# apollo3p register map
Vendor: Ambiq Micro; Series: Apollo; File version: 1.0
CPU: CM4 r1p0, little endian, MPU, FPU, I-cache, D-cache, VTOR, ITCM, DTCM, 3 interrupt priority bits, 0 interrupts
Registers are 32-bit, read-write, reset 0x0 unless marked. A register's access mark holds for its fields unless they carry their own. Offsets are from the block's base; [hi:lo] are bit positions; {n}, {i} and the like mark numbered series; 'fields as' and 'values as' point back to an identical list.

## CTIMER (part 2 of 3) — Counter/Timer
Base 0x40008000
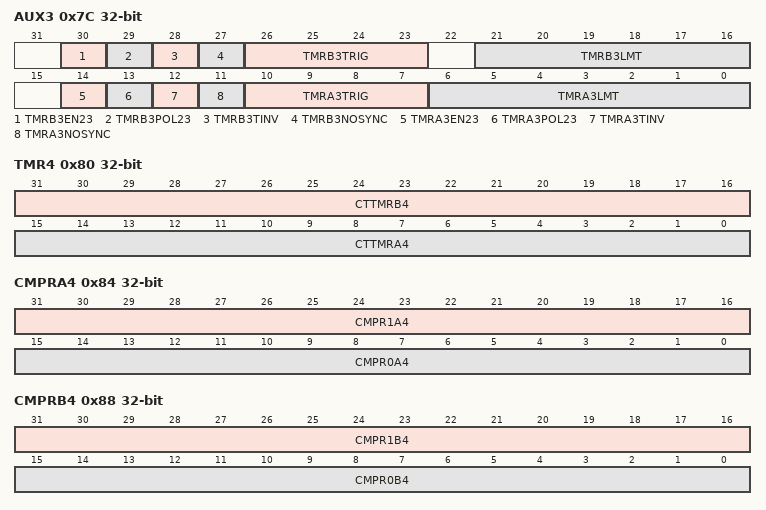
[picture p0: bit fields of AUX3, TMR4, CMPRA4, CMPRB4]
0x7C AUX3 — Control bit fields for both halves of timer 0.
  [30] TMRB3EN23 — Counter/Timer B3 Upper compare enable.
    1=DIS (Disable enhanced functions.); 0=EN (Enable enhanced functions.)
  [29] TMRB3POL23 — Upper output polarity
    0=NORM (Upper output normal polarity); 1=INV (Upper output inverted polarity.)
  [28] TMRB3TINV — Counter/Timer B3 Invert on trigger.
    0=DIS (Disable invert on trigger); 1=EN (Enable invert on trigger)
  [27] TMRB3NOSYNC — Source clock synchronization control.
    0=DIS (Synchronization on source clock); 1=NOSYNC (No synchronization on source clock)
  [26:23] TMRB3TRIG — Counter/Timer B3 Trigger Select.
    0=DIS (Trigger source is disabled.); 1=A3OUT (Trigger source is CTIMERA3 OUT.); 2=B2OUT (Trigger source is CTIMERB2 OUT.); 3=A2OUT (Trigger source is CTIMERA2 OUT.); 4=A4OUT (Trigger source is CTIMERA4 OUT.); 5=B4OUT (Trigger source is CTIMERB4 OUT.); 6=A6OUT (Trigger source is CTIMERA6 OUT.); 7=B6OUT (Trigger source is CTIMERB6 OUT.); 8=B5OUT2 (Trigger source is CTIMERB5 OUT2.); 9=A5OUT2 (Trigger source is CTIMERA5 OUT2.); 10=A1OUT2 (Trigger source is CTIMERA1 OUT2.); 11=B1OUT2 (Trigger source is CTIMERB1 OUT2.); 12=A6OUT2DUAL (Trigger source is CTIMERA6 OUT2, dual edge.); 13=A7OUT2DUAL (Trigger source is CTIMERA7 OUT2, dual edge.); 14=B2OUT2DUAL (Trigger source is CTIMERB2 OUT2, dual edge.); 15=A2OUT2DUAL (Trigger source is CTIMERA2 OUT2, dual edge.)
  [21:16] TMRB3LMT — Counter/Timer B3 Pattern Limit Count.
  [14] TMRA3EN23 — Counter/Timer A3 Upper compare enable.
    values as TMRB3EN23
  [13] TMRA3POL23 — Counter/Timer A3 Upper output polarity
    values as TMRB3POL23
  [12] TMRA3TINV — Counter/Timer A3 Invert on trigger.
    values as TMRB3TINV
  [11] TMRA3NOSYNC — Source clock synchronization control.
    values as TMRB3NOSYNC
  [10:7] TMRA3TRIG — Counter/Timer A3 Trigger Select.
    0=DIS (Trigger source is disabled.); 1=B3OUT (Trigger source is CTIMERB3 OUT.); 2=B2OUT (Trigger source is CTIMERB2 OUT.); 3=A2OUT (Trigger source is CTIMERA2 OUT.); 4=A4OUT (Trigger source is CTIMERA4 OUT.); 5=B4OUT (Trigger source is CTIMERB4 OUT.); 6=A7OUT (Trigger source is CTIMERA7 OUT.); 7=B7OUT (Trigger source is CTIMERB7 OUT.); 8=B5OUT2 (Trigger source is CTIMERB5 OUT2.); 9=A5OUT2 (Trigger source is CTIMERA5 OUT2.); 10=A1OUT2 (Trigger source is CTIMERA1 OUT2.); 11=B1OUT2 (Trigger source is CTIMERB1 OUT2.); 12=A6OUT2DUAL (Trigger source is CTIMERA6 OUT2, dual edge.); 13=A7OUT2DUAL (Trigger source is CTIMERA7 OUT2, dual edge.); 14=B2OUT2DUAL (Trigger source is CTIMERB2 OUT2, dual edge.); 15=A2OUT2DUAL (Trigger source is CTIMERA2 OUT2, dual edge.)
  [6:0] TMRA3LMT — Counter/Timer A3 Pattern Limit Count.
0x80 TMR4 — This register holds the running time or event count, either for each 16 bit half or for the whole 32 bit count when the pair is linked.
  [31:16] CTTMRB4 — Counter/Timer B4.
  [15:0] CTTMRA4 — Counter/Timer A4.
0x84 CMPRA4 — Compare limits for timer half A.
  [31:16] CMPR1A4 — Counter/Timer A4 Compare Register 1. Holds the upper limit for timer half A.
  [15:0] CMPR0A4 — Counter/Timer A4 Compare Register 0. Holds the lower limit for timer half A.
0x88 CMPRB4 — Compare limits for timer half B.
  [31:16] CMPR1B4 — Counter/Timer B4 Compare Register 1. Holds the upper limit for timer half B.
  [15:0] CMPR0B4 — Counter/Timer B4 Compare Register 0. Holds the lower limit for timer half B.
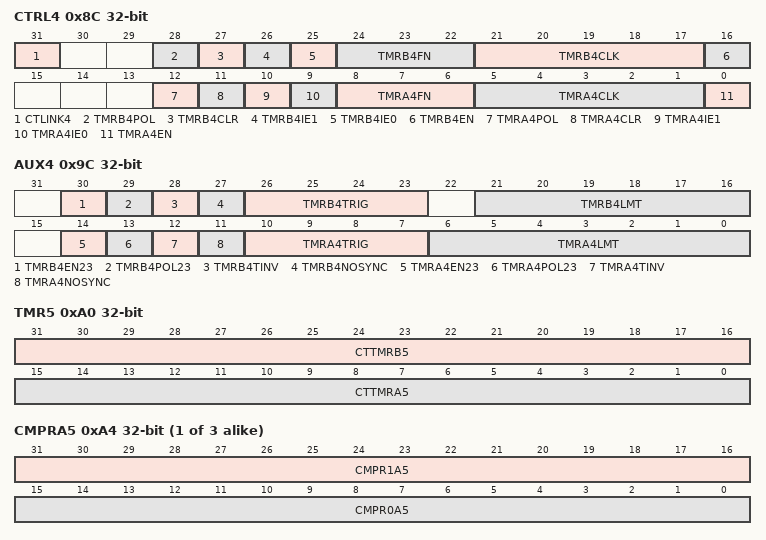
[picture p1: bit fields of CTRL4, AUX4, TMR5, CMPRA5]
0x8C CTRL4 — Control bit fields for both halves of timer 4.
  [31] CTLINK4 — Counter/Timer A4/B4 Link bit.
    0=TWO_16BIT_TIMERS (Use A4/B4 timers as two independent 16-bit timers (default).); 1=32BIT_TIMER (Link A4/B4 timers into a single 32-bit timer.)
  [28] TMRB4POL — Counter/Timer B4 output polarity.
    0=NORMAL (The polarity of the TMRPINB4 pin is the same as the timer output.); 1=INVERTED (The polarity of the TMRPINB4 pin is the inverse of the timer output.)
  [27] TMRB4CLR — Counter/Timer B4 Clear bit.
    0=RUN (Allow counter/timer B4 to run); 1=CLEAR (Holds counter/timer B4 at 0x0000.)
  [26] TMRB4IE1 — Counter/Timer B4 Interrupt Enable bit for COMPR1.
    0=DIS (Disable counter/timer B4 from generating an interrupt based on COMPR1.); 1=EN (Enable counter/timer B4 to generate an interrupt based on COMPR1.)
  [25] TMRB4IE0 — Counter/Timer B4 Interrupt Enable bit for COMPR0.
    0=DIS (Disable counter/timer B4 from generating an interrupt based on COMPR0.); 1=EN (Enable counter/timer B4 to generate an interrupt based on COMPR0)
  [24:22] TMRB4FN — Counter/Timer B4 Function Select.
    0=SINGLECOUNT (Single count (output toggles and sticks). Count to CMPR0B4, stop.); 1=REPEATEDCOUNT (Repeated count (periodic 1-clock-cycle-wide pulses). Count to CMPR0B4, restart.); 2=PULSE_ONCE (Pulse once (aka one-shot). Count to CMPR0B4, assert, count to CMPR1B4, deassert, stop.); 3=PULSE_CONT (Pulse continuously. Count to CMPR0B4, assert, count to CMPR1B4, deassert, restart.); 4=SINGLEPATTERN; 5=REPEATPATTERN (Repeated pattern.); 6=CONTINUOUS (Continuous run (aka Free Run). Count continuously.); 7=ALTPWN (Alternate PWM)
  [21:17] TMRB4CLK — Counter/Timer B4 Clock Select.
    0=TMRPIN (Clock source is TMRPINB.); 1=HFRC_DIV4 (Clock source is the HFRC / 4); 2=HFRC_DIV16 (Clock source is HFRC / 16); 3=HFRC_DIV256 (Clock source is HFRC / 256); 4=HFRC_DIV1024 (Clock source is HFRC / 1024); 5=HFRC_DIV4K (Clock source is HFRC / 4096); 6=XT (Clock source is the XT (uncalibrated).); 7=XT_DIV2 (Clock source is XT / 2); 8=XT_DIV16 (Clock source is XT / 16); 9=XT_DIV128 (Clock source is XT / 128); 10=LFRC_DIV2 (Clock source is LFRC / 2); 11=LFRC_DIV32 (Clock source is LFRC / 32); 12=LFRC_DIV1K (Clock source is LFRC / 1024); 13=LFRC (Clock source is LFRC); 14=RTC_100HZ (Clock source is 100 Hz from the current RTC oscillator.); 15=HCLK_DIV4 (Clock source is HCLK / 4 (note: this clock is only available when MCU is in active mode)); 16=XT_DIV4 (Clock source is XT / 4); 17=XT_DIV8 (Clock source is XT / 8); 18=XT_DIV32 (Clock source is XT / 32); 20=CTMRA4 (Clock source is CTIMERA4 OUT.); 21=CTMRA1 (Clock source is CTIMERA1 OUT.); 22=CTMRB1 (Clock source is CTIMERB1 OUT.); 23=CTMRA5 (Clock source is CTIMERA5 OUT.); 24=CTMRB5 (Clock source is CTIMERB5 OUT.); 25=CTMRB0 (Clock source is CTIMERB0 OUT.); 26=CTMRB2 (Clock source is CTIMERB2 OUT.); 27=CTMRB3 (Clock source is CTIMERB3 OUT.); 28=CTMRB6 (Clock source is CTIMERB6 OUT.); 29=BUCKBLE (Clock source is BLE buck converter TON pulses.); 30=BUCKB (Clock source is Memory buck converter TON pulses.); 31=BUCKA (Clock source is CPU buck converter TON pulses.)
  [16] TMRB4EN — Counter/Timer B4 Enable bit.
    0=DIS (Counter/Timer B4 Disable.); 1=EN (Counter/Timer B4 Enable.)
  [12] TMRA4POL — Counter/Timer A4 output polarity.
    0=NORMAL (The polarity of the TMRPINA4 pin is the same as the timer output.); 1=INVERTED (The polarity of the TMRPINA4 pin is the inverse of the timer output.)
  [11] TMRA4CLR — Counter/Timer A4 Clear bit.
    0=RUN (Allow counter/timer A4 to run); 1=CLEAR (Holds counter/timer A4 at 0x0000.)
  [10] TMRA4IE1 — Counter/Timer A4 Interrupt Enable bit based on COMPR1.
    0=DIS (Disable counter/timer A4 from generating an interrupt based on COMPR1.); 1=EN (Enable counter/timer A4 to generate an interrupt based on COMPR1.)
  [9] TMRA4IE0 — Counter/Timer A4 Interrupt Enable bit based on COMPR0.
    0=DIS (Disable counter/timer A4 from generating an interrupt based on COMPR0.); 1=EN (Enable counter/timer A4 to generate an interrupt based on COMPR0.)
  [8:6] TMRA4FN — Counter/Timer A4 Function Select.
    0=SINGLECOUNT (Single count (output toggles and sticks). Count to CMPR0A4, stop.); 1=REPEATEDCOUNT (Repeated count (periodic 1-clock-cycle-wide pulses). Count to CMPR0A4, restart.); 2=PULSE_ONCE (Pulse once (aka one-shot). Count to CMPR0A4, assert, count to CMPR1A4, deassert, stop.); 3=PULSE_CONT (Pulse continuously. Count to CMPR0A4, assert, count to CMPR1A4, deassert, restart.); 4=SINGLEPATTERN; 5=REPEATPATTERN (Repeated pattern.); 6=CONTINUOUS (Continuous run (aka Free Run). Count continuously.); 7=ALTPWN (Alternate PWM)
  [5:1] TMRA4CLK — Counter/Timer A4 Clock Select.
    0=TMRPIN (Clock source is TMRPINA.); 1=HFRC_DIV4 (Clock source is the HFRC / 4); 2=HFRC_DIV16 (Clock source is HFRC / 16); 3=HFRC_DIV256 (Clock source is HFRC / 256); 4=HFRC_DIV1024 (Clock source is HFRC / 1024); 5=HFRC_DIV4K (Clock source is HFRC / 4096); 6=XT (Clock source is the XT (uncalibrated).); 7=XT_DIV2 (Clock source is XT / 2); 8=XT_DIV16 (Clock source is XT / 16); 9=XT_DIV128 (Clock source is XT / 128); 10=LFRC_DIV2 (Clock source is LFRC / 2); 11=LFRC_DIV32 (Clock source is LFRC / 32); 12=LFRC_DIV1K (Clock source is LFRC / 1024); 13=LFRC (Clock source is LFRC); 14=RTC_100HZ (Clock source is 100 Hz from the current RTC oscillator.); 15=HCLK_DIV4 (Clock source is HCLK / 4. (note: this clock is only available when MCU is in active mode)); 16=XT_DIV4 (Clock source is XT / 4); 17=XT_DIV8 (Clock source is XT / 8); 18=XT_DIV32 (Clock source is XT / 32); 20=CTMRB4 (Clock source is CTIMERB4 OUT.); 21=CTMRA1 (Clock source is CTIMERA1 OUT.); 22=CTMRB1 (Clock source is CTIMERB1 OUT.); 23=CTMRA5 (Clock source is CTIMERA5 OUT.); 24=CTMRB5 (Clock source is CTIMERB5 OUT.); 25=CTMRB0 (Clock source is CTIMERB0 OUT.); 26=CTMRB2 (Clock source is CTIMERB2 OUT.); 27=CTMRB3 (Clock source is CTIMERB3 OUT.); 28=CTMRB6 (Clock source is CTIMERB6 OUT.); 29=BUCKBLE (Clock source is BLE buck converter TON pulses.); 30=BUCKB (Clock source is Memory buck converter TON pulses.); 31=BUCKA (Clock source is CPU buck converter TON pulses.)
  [0] TMRA4EN — Counter/Timer A4 Enable bit.
    0=DIS (Counter/Timer A4 Disable.); 1=EN (Counter/Timer A4 Enable.)
0x9C AUX4 — Control bit fields for both halves of timer 4.
  [30] TMRB4EN23 — Counter/Timer B4 Upper compare enable.
    values as AUX3.TMRB3EN23
  [29] TMRB4POL23 — Upper output polarity
    values as AUX3.TMRB3POL23
  [28] TMRB4TINV — Counter/Timer B4 Invert on trigger.
    values as AUX3.TMRB3TINV
  [27] TMRB4NOSYNC — Source clock synchronization control.
    values as AUX3.TMRB3NOSYNC
  [26:23] TMRB4TRIG — Counter/Timer B4 Trigger Select.
    0=DIS (Trigger source is disabled.); 1=A4OUT (Trigger source is CTIMERA4 OUT.); 2=B3OUT (Trigger source is CTIMERB3 OUT.); 3=A3OUT (Trigger source is CTIMERA3 OUT.); 4=A7OUT (Trigger source is CTIMERA7 OUT.); 5=B7OUT (Trigger source is CTIMERB7 OUT.); 6=A1OUT (Trigger source is CTIMERA1 OUT.); 7=B1OUT (Trigger source is CTIMERB1 OUT.); 8=B3OUT2 (Trigger source is CTIMERB3 OUT2.); 9=A3OUT2 (Trigger source is CTIMERA3 OUT2.); 10=A1OUT2 (Trigger source is CTIMERA1 OUT2.); 11=B1OUT2 (Trigger source is CTIMERB1 OUT2.); 12=A6OUT2DUAL (Trigger source is CTIMERA6 OUT2, dual edge.); 13=A7OUT2DUAL (Trigger source is CTIMERA7 OUT2, dual edge.); 14=B5OUT2DUAL (Trigger source is CTIMERB5 OUT2, dual edge.); 15=A5OUT2DUAL (Trigger source is CTIMERA5 OUT2, dual edge.)
  [21:16] TMRB4LMT — Counter/Timer B4 Pattern Limit Count.
  [14] TMRA4EN23 — Counter/Timer A4 Upper compare enable.
    values as AUX3.TMRB3EN23
  [13] TMRA4POL23 — Counter/Timer A4 Upper output polarity
    values as AUX3.TMRB3POL23
  [12] TMRA4TINV — Counter/Timer A4 Invert on trigger.
    values as AUX3.TMRB3TINV
  [11] TMRA4NOSYNC — Source clock synchronization control.
    values as AUX3.TMRB3NOSYNC
  [10:7] TMRA4TRIG — Counter/Timer A4 Trigger Select.
    0=DIS (Trigger source is disabled.); 1=STIMER (Trigger source is STimer Interrupt. Only Active When CTLINK==1 and TMRB4TRIG!=0. TMRB4TRIG selects an STIMER interrupt); 2=B3OUT (Trigger source is CTIMERB3 OUT.); 3=A3OUT (Trigger source is CTIMERA3 OUT.); 4=A6OUT (Trigger source is CTIMERA6 OUT.); 5=B6OUT (Trigger source is CTIMERB6 OUT.); 6=A2OUT (Trigger source is CTIMERA2 OUT.); 7=B2OUT (Trigger source is CTIMERB2 OUT.); 8=B3OUT2 (Trigger source is CTIMERB3 OUT2.); 9=A3OUT2 (Trigger source is CTIMERA3 OUT2.); 10=A1OUT2 (Trigger source is CTIMERA1 OUT2.); 11=B1OUT2 (Trigger source is CTIMERB1 OUT2.); 12=A6OUT2DUAL (Trigger source is CTIMERA6 OUT2, dual edge.); 13=A7OUT2DUAL (Trigger source is CTIMERA7 OUT2, dual edge.); 14=B5OUT2DUAL (Trigger source is CTIMERB5 OUT2, dual edge.); 15=A5OUT2DUAL (Trigger source is CTIMERA5 OUT2, dual edge.)
  [6:0] TMRA4LMT — Counter/Timer A4 Pattern Limit Count.
0xA0 TMR5 — This register holds the running time or event count, either for each 16 bit half or for the whole 32 bit count when the pair is linked.
  [31:16] CTTMRB5 — Counter/Timer B5.
  [15:0] CTTMRA5 — Counter/Timer A5.
{0x4+0x20*i} CMPRA{i} (i=5..7) — This register holds the compare limits for timer half A.
  [31:16] CMPR1A{i} — Counter/Timer A{i} Compare Register 1.
  [15:0] CMPR0A{i} — Counter/Timer A{i} Compare Register 0.
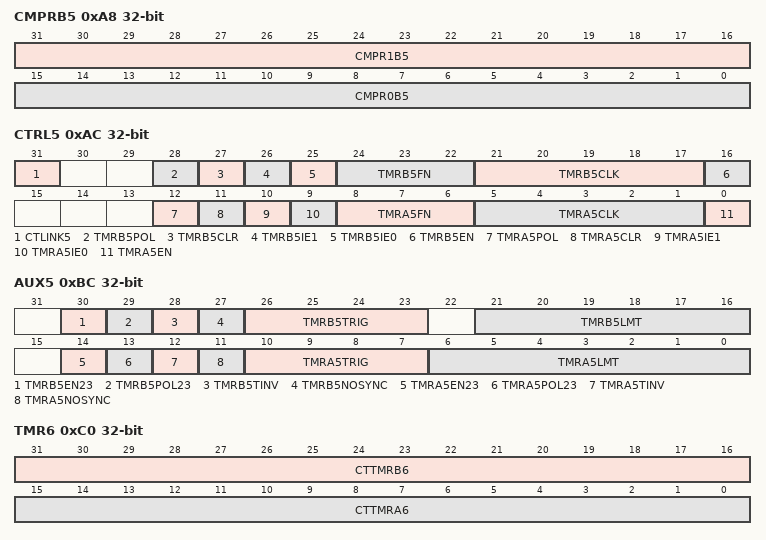
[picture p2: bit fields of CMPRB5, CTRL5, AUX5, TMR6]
0xA8 CMPRB5 — This register holds the compare limits for timer half B.
  [31:16] CMPR1B5 — Counter/Timer B5 Compare Register 1.
  [15:0] CMPR0B5 — Counter/Timer B5 Compare Register 0.
0xAC CTRL5 — Control bit fields for both halves of timer 0.
  [31] CTLINK5 — Counter/Timer A5/B5 Link bit.
    0=TWO_16BIT_TIMERS (Use A5/B5 timers as two independent 16-bit timers (default).); 1=32BIT_TIMER (Link A5/B5 timers into a single 32-bit timer.)
  [28] TMRB5POL — Counter/Timer B5 output polarity.
    0=NORMAL (The polarity of the TMRPINB5 pin is the same as the timer output.); 1=INVERTED (The polarity of the TMRPINB5 pin is the inverse of the timer output.)
  [27] TMRB5CLR — Counter/Timer B5 Clear bit.
    0=RUN (Allow counter/timer B5 to run); 1=CLEAR (Holds counter/timer B5 at 0x0000.)
  [26] TMRB5IE1 — Counter/Timer B5 Interrupt Enable bit for COMPR1.
    0=DIS (Disable counter/timer B5 from generating an interrupt based on COMPR1.); 1=EN (Enable counter/timer B5 to generate an interrupt based on COMPR1.)
  [25] TMRB5IE0 — Counter/Timer B5 Interrupt Enable bit for COMPR0.
    0=DIS (Disable counter/timer B5 from generating an interrupt based on COMPR0.); 1=EN (Enable counter/timer B5 to generate an interrupt based on COMPR0)
  [24:22] TMRB5FN — Counter/Timer B5 Function Select.
    0=SINGLECOUNT (Single count (output toggles and sticks). Count to CMPR0B5, stop.); 1=REPEATEDCOUNT (Repeated count (periodic 1-clock-cycle-wide pulses). Count to CMPR0B5, restart.); 2=PULSE_ONCE (Pulse once (aka one-shot). Count to CMPR0B5, assert, count to CMPR1B5, deassert, stop.); 3=PULSE_CONT (Pulse continuously. Count to CMPR0B5, assert, count to CMPR1B5, deassert, restart.); 4=SINGLEPATTERN; 5=REPEATPATTERN (Repeated pattern.); 6=CONTINUOUS (Continuous run (aka Free Run). Count continuously.); 7=ALTPWN (Alternate PWM)
  [21:17] TMRB5CLK — Counter/Timer B5 Clock Select.
    0=TMRPIN (Clock source is TMRPINB.); 1=HFRC_DIV4 (Clock source is the HFRC / 4); 2=HFRC_DIV16 (Clock source is HFRC / 16); 3=HFRC_DIV256 (Clock source is HFRC / 256); 4=HFRC_DIV1024 (Clock source is HFRC / 1024); 5=HFRC_DIV4K (Clock source is HFRC / 4096); 6=XT (Clock source is the XT (uncalibrated).); 7=XT_DIV2 (Clock source is XT / 2); 8=XT_DIV16 (Clock source is XT / 16); 9=XT_DIV128 (Clock source is XT / 128); 10=LFRC_DIV2 (Clock source is LFRC / 2); 11=LFRC_DIV32 (Clock source is LFRC / 32); 12=LFRC_DIV1K (Clock source is LFRC / 1024); 13=LFRC (Clock source is LFRC); 14=RTC_100HZ (Clock source is 100 Hz from the current RTC oscillator.); 15=HCLK_DIV4 (Clock source is HCLK / 4 (note: this clock is only available when MCU is in active mode)); 16=XT_DIV4 (Clock source is XT / 4); 17=XT_DIV8 (Clock source is XT / 8); 18=XT_DIV32 (Clock source is XT / 32); 20=CTMRA5 (Clock source is CTIMERA5 OUT.); 21=CTMRA0 (Clock source is CTIMERA0 OUT.); 22=CTMRB0 (Clock source is CTIMERB0 OUT.); 23=CTMRA6 (Clock source is CTIMERA6 OUT.); 24=CTMRB6 (Clock source is CTIMERB6 OUT.); {v}=CTMRB{v-24} (Clock source is CTIMERB{v-24} OUT.) (v=25..28); 29=BUCKBLE (Clock source is BLE buck converter TON pulses.); 30=BUCKB (Clock source is Memory buck converter TON pulses.); 31=BUCKA (Clock source is CPU buck converter TON pulses.)
  [16] TMRB5EN — Counter/Timer B5 Enable bit.
    0=DIS (Counter/Timer B5 Disable.); 1=EN (Counter/Timer B5 Enable.)
  [12] TMRA5POL — Counter/Timer A5 output polarity.
    0=NORMAL (The polarity of the TMRPINA5 pin is the same as the timer output.); 1=INVERTED (The polarity of the TMRPINA5 pin is the inverse of the timer output.)
  [11] TMRA5CLR — Counter/Timer A5 Clear bit.
    0=RUN (Allow counter/timer A5 to run); 1=CLEAR (Holds counter/timer A5 at 0x0000.)
  [10] TMRA5IE1 — Counter/Timer A5 Interrupt Enable bit based on COMPR1.
    0=DIS (Disable counter/timer A5 from generating an interrupt based on COMPR1.); 1=EN (Enable counter/timer A5 to generate an interrupt based on COMPR1.)
  [9] TMRA5IE0 — Counter/Timer A5 Interrupt Enable bit based on COMPR0.
    0=DIS (Disable counter/timer A5 from generating an interrupt based on COMPR0.); 1=EN (Enable counter/timer A5 to generate an interrupt based on COMPR0.)
  [8:6] TMRA5FN — Counter/Timer A5 Function Select.
    0=SINGLECOUNT (Single count (output toggles and sticks). Count to CMPR0A5, stop.); 1=REPEATEDCOUNT (Repeated count (periodic 1-clock-cycle-wide pulses). Count to CMPR0A5, restart.); 2=PULSE_ONCE (Pulse once (aka one-shot). Count to CMPR0A5, assert, count to CMPR1A5, deassert, stop.); 3=PULSE_CONT (Pulse continuously. Count to CMPR0A5, assert, count to CMPR1A5, deassert, restart.); 4=SINGLEPATTERN; 5=REPEATPATTERN (Repeated pattern.); 6=CONTINUOUS (Continuous run (aka Free Run). Count continuously.); 7=ALTPWN (Alternate PWM)
  [5:1] TMRA5CLK — Counter/Timer A5 Clock Select.
    0=TMRPIN (Clock source is TMRPINA.); 1=HFRC_DIV4 (Clock source is the HFRC / 4); 2=HFRC_DIV16 (Clock source is HFRC / 16); 3=HFRC_DIV256 (Clock source is HFRC / 256); 4=HFRC_DIV1024 (Clock source is HFRC / 1024); 5=HFRC_DIV4K (Clock source is HFRC / 4096); 6=XT (Clock source is the XT (uncalibrated).); 7=XT_DIV2 (Clock source is XT / 2); 8=XT_DIV16 (Clock source is XT / 16); 9=XT_DIV128 (Clock source is XT / 128); 10=LFRC_DIV2 (Clock source is LFRC / 2); 11=LFRC_DIV32 (Clock source is LFRC / 32); 12=LFRC_DIV1K (Clock source is LFRC / 1024); 13=LFRC (Clock source is LFRC); 14=RTC_100HZ (Clock source is 100 Hz from the current RTC oscillator.); 15=HCLK_DIV4 (Clock source is HCLK / 4 (note: this clock is only available when MCU is in active mode)); 16=XT_DIV4 (Clock source is XT / 4); 17=XT_DIV8 (Clock source is XT / 8); 18=XT_DIV32 (Clock source is XT / 32); 20=CTMRB5 (Clock source is CTIMERB5 OUT.); 21=CTMRA0 (Clock source is CTIMERA0 OUT.); 22=CTMRB0 (Clock source is CTIMERB0 OUT.); 23=CTMRA6 (Clock source is CTIMERA6 OUT.); 24=CTMRB6 (Clock source is CTIMERB6 OUT.); {v}=CTMRB{v-24} (Clock source is CTIMERB{v-24} OUT.) (v=25..28); 29=BUCKBLE (Clock source is BLE buck converter TON pulses.); 30=BUCKB (Clock source is Memory buck converter TON pulses.); 31=BUCKA (Clock source is CPU buck converter TON pulses.)
  [0] TMRA5EN — Counter/Timer A5 Enable bit.
    0=DIS (Counter/Timer A5 Disable.); 1=EN (Counter/Timer A5 Enable.)
0xBC AUX5 — Control bit fields for both halves of timer 0.
  [30] TMRB5EN23 — Counter/Timer B5 Upper compare enable.
    values as AUX3.TMRB3EN23
  [29] TMRB5POL23 — Upper output polarity
    values as AUX3.TMRB3POL23
  [28] TMRB5TINV — Counter/Timer B5 Invert on trigger.
    values as AUX3.TMRB3TINV
  [27] TMRB5NOSYNC — Source clock synchronization control.
    values as AUX3.TMRB3NOSYNC
  [26:23] TMRB5TRIG — Counter/Timer B5 Trigger Select.
    0=DIS (Trigger source is disabled.); 1=A5OUT (Trigger source is CTIMERA5 OUT.); 2=B3OUT (Trigger source is CTIMERB3 OUT.); 3=A3OUT (Trigger source is CTIMERA3 OUT.); 4=A6OUT (Trigger source is CTIMERA6 OUT.); 5=B6OUT (Trigger source is CTIMERB6 OUT.); 6=A1OUT (Trigger source is CTIMERA1 OUT.); 7=B1OUT (Trigger source is CTIMERB1 OUT.); 8=B3OUT2 (Trigger source is CTIMERB3 OUT2.); 9=A3OUT2 (Trigger source is CTIMERA3 OUT2.); 10=A0OUT2 (Trigger source is CTIMERA0 OUT2.); 11=B0OUT2 (Trigger source is CTIMERB0 OUT2.); 12=A6OUT2DUAL (Trigger source is CTIMERA6 OUT2, dual edge.); 13=A7OUT2DUAL (Trigger source is CTIMERA7 OUT2, dual edge.); 14=B4OUT2DUAL (Trigger source is CTIMERB4 OUT2, dual edge.); 15=A4OUT2DUAL (Trigger source is CTIMERA4 OUT2, dual edge.)
  [21:16] TMRB5LMT — Counter/Timer B5 Pattern Limit Count.
  [14] TMRA5EN23 — Counter/Timer A5 Upper compare enable.
    values as AUX3.TMRB3EN23
  [13] TMRA5POL23 — Counter/Timer A5 Upper output polarity
    0=NORMAL (Upper output normal polarity); 1=INV (Upper output inverted polarity.)
  [12] TMRA5TINV — Counter/Timer A5 Invert on trigger.
    values as AUX3.TMRB3TINV
  [11] TMRA5NOSYNC — Source clock synchronization control.
    values as AUX3.TMRB3NOSYNC
  [10:7] TMRA5TRIG — Counter/Timer A5 Trigger Select.
    0=DIS (Trigger source is disabled.); 1=STIMER (Trigger source is STimer Interrupt. Only Active When CTLINK==1 and TMRB5TRIG!=0. TMRB5TRIG selects an STIMER interrupt); 2=B3OUT (Trigger source is CTIMERB3 OUT.); 3=A3OUT (Trigger source is CTIMERA3 OUT.); 4=A4OUT (Trigger source is CTIMERA4 OUT.); 5=B4OUT (Trigger source is CTIMERB4 OUT.); 6=A2OUT (Trigger source is CTIMERA2 OUT.); 7=B2OUT (Trigger source is CTIMERB2 OUT.); 8=B3OUT2 (Trigger source is CTIMERB3 OUT2.); 9=A3OUT2 (Trigger source is CTIMERA3 OUT2.); 10=A0OUT2 (Trigger source is CTIMERA0 OUT2.); 11=B0OUT2 (Trigger source is CTIMERB0 OUT2.); 12=A6OUT2DUAL (Trigger source is CTIMERA6 OUT2, dual edge.); 13=A7OUT2DUAL (Trigger source is CTIMERA7 OUT2, dual edge.); 14=B4OUT2DUAL (Trigger source is CTIMERB4 OUT2, dual edge.); 15=A4OUT2DUAL (Trigger source is CTIMERA4 OUT2, dual edge.)
  [6:0] TMRA5LMT — Counter/Timer A5 Pattern Limit Count.
0xC0 TMR6 — Counter/Timer 6
  [31:16] CTTMRB6 — Counter/Timer B6.
  [15:0] CTTMRA6 — Counter/Timer A6.
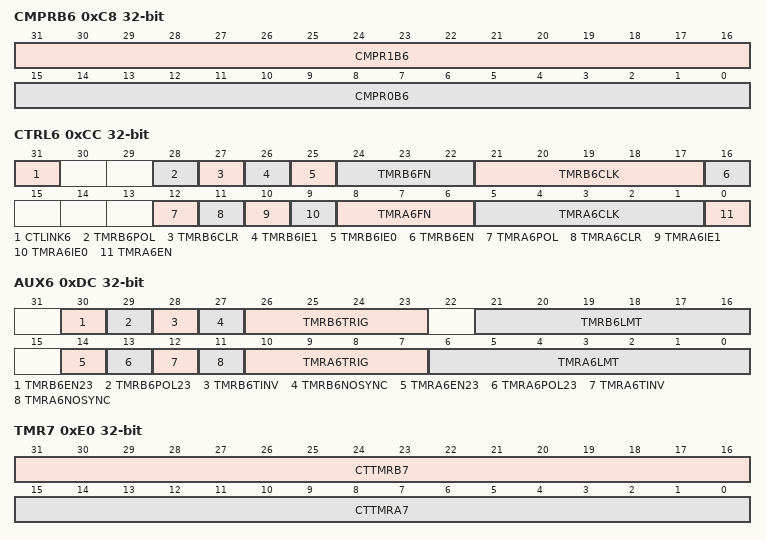
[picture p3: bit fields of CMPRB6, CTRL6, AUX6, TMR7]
0xC8 CMPRB6 — This register holds the compare limits for timer half B.
  [31:16] CMPR1B6 — Counter/Timer B6 Compare Register 1.
  [15:0] CMPR0B6 — Counter/Timer B6 Compare Register 0.
0xCC CTRL6 — This register holds the control bit fields for both halves of timer 6.
  [31] CTLINK6 — Counter/Timer A6/B6 Link bit.
    0=TWO_16BIT_TIMERS (Use A6/B6 timers as two independent 16-bit timers (default).); 1=32BIT_TIMER (Link A6/B6 timers into a single 32-bit timer.)
  [28] TMRB6POL — Counter/Timer B6 output polarity.
    0=NORMAL (The polarity of the TMRPINB6 pin is the same as the timer output.); 1=INVERTED (The polarity of the TMRPINB6 pin is the inverse of the timer output.)
  [27] TMRB6CLR — Counter/Timer B6 Clear bit.
    0=RUN (Allow counter/timer B6 to run); 1=CLEAR (Holds counter/timer B6 at 0x0000.)
  [26] TMRB6IE1 — Counter/Timer B6 Interrupt Enable bit for COMPR1.
    0=DIS (Disable counter/timer B6 from generating an interrupt based on COMPR1.); 1=EN (Enable counter/timer B6 to generate an interrupt based on COMPR1.)
  [25] TMRB6IE0 — Counter/Timer B6 Interrupt Enable bit for COMPR0.
    0=DIS (Disable counter/timer B6 from generating an interrupt based on COMPR0.); 1=EN (Enable counter/timer B6 to generate an interrupt based on COMPR0)
  [24:22] TMRB6FN — Counter/Timer B6 Function Select.
    0=SINGLECOUNT (Single count (output toggles and sticks). Count to CMPR0B6, stop.); 1=REPEATEDCOUNT (Repeated count (periodic 1-clock-cycle-wide pulses). Count to CMPR0B6, restart.); 2=PULSE_ONCE (Pulse once (aka one-shot). Count to CMPR0B6, assert, count to CMPR1B6, deassert, stop.); 3=PULSE_CONT (Pulse continuously. Count to CMPR0B6, assert, count to CMPR1B6, deassert, restart.); 4=SINGLEPATTERN; 5=REPEATPATTERN (Repeated pattern.); 6=CONTINUOUS (Continuous run (aka Free Run). Count continuously.); 7=ALTPWN (Alternate PWM)
  [21:17] TMRB6CLK — Counter/Timer B6 Clock Select.
    0=TMRPIN (Clock source is TMRPINB.); 1=HFRC_DIV4 (Clock source is the HFRC / 4); 2=HFRC_DIV16 (Clock source is HFRC / 16); 3=HFRC_DIV256 (Clock source is HFRC / 256); 4=HFRC_DIV1024 (Clock source is HFRC / 1024); 5=HFRC_DIV4K (Clock source is HFRC / 4096); 6=XT (Clock source is the XT (uncalibrated).); 7=XT_DIV2 (Clock source is XT / 2); 8=XT_DIV16 (Clock source is XT / 16); 9=XT_DIV128 (Clock source is XT / 128); 10=LFRC_DIV2 (Clock source is LFRC / 2); 11=LFRC_DIV32 (Clock source is LFRC / 32); 12=LFRC_DIV1K (Clock source is LFRC / 1024); 13=LFRC (Clock source is LFRC); 14=RTC_100HZ (Clock source is 100 Hz from the current RTC oscillator.); 15=HCLK_DIV4 (Clock source is HCLK / 4 (note: this clock is only available when MCU is in active mode)); 16=XT_DIV4 (Clock source is XT / 4); 17=XT_DIV8 (Clock source is XT / 8); 18=XT_DIV32 (Clock source is XT / 32); 20=CTMRA6 (Clock source is CTIMERA6 OUT.); 21=CTMRA3 (Clock source is CTIMERA3 OUT.); 22=CTMRB3 (Clock source is CTIMERB3 OUT.); 23=CTMRA7 (Clock source is CTIMERA7 OUT.); 24=CTMRB7 (Clock source is CTIMERB7 OUT.); 25=CTMRB0 (Clock source is CTIMERB0 OUT.); 26=CTMRB1 (Clock source is CTIMERB1 OUT.); 27=CTMRB2 (Clock source is CTIMERB2 OUT.); 28=CTMRB4 (Clock source is CTIMERB4 OUT.); 29=BUCKBLE (Clock source is BLE buck converter TON pulses.); 30=BUCKB (Clock source is Memory buck converter TON pulses.); 31=BUCKA (Clock source is CPU buck converter TON pulses.)
  [16] TMRB6EN — Counter/Timer B6 Enable bit.
    0=DIS (Counter/Timer B6 Disable.); 1=EN (Counter/Timer B6 Enable.)
  [12] TMRA6POL — Counter/Timer A6 output polarity.
    0=NORMAL (The polarity of the TMRPINA6 pin is the same as the timer output.); 1=INVERTED (The polarity of the TMRPINA6 pin is the inverse of the timer output.)
  [11] TMRA6CLR — Counter/Timer A6 Clear bit.
    0=RUN (Allow counter/timer A6 to run); 1=CLEAR (Holds counter/timer A6 at 0x0000.)
  [10] TMRA6IE1 — Counter/Timer A6 Interrupt Enable bit based on COMPR1.
    0=DIS (Disable counter/timer A6 from generating an interrupt based on COMPR1.); 1=EN (Enable counter/timer A6 to generate an interrupt based on COMPR1.)
  [9] TMRA6IE0 — Counter/Timer A6 Interrupt Enable bit based on COMPR0.
    0=DIS (Disable counter/timer A6 from generating an interrupt based on COMPR0.); 1=EN (Enable counter/timer A6 to generate an interrupt based on COMPR0.)
  [8:6] TMRA6FN — Counter/Timer A6 Function Select.
    0=SINGLECOUNT (Single count (output toggles and sticks). Count to CMPR0A6, stop.); 1=REPEATEDCOUNT (Repeated count (periodic 1-clock-cycle-wide pulses). Count to CMPR0A6, restart.); 2=PULSE_ONCE (Pulse once (aka one-shot). Count to CMPR0A6, assert, count to CMPR1A6, deassert, stop.); 3=PULSE_CONT (Pulse continuously. Count to CMPR0A6, assert, count to CMPR1A6, deassert, restart.); 4=SINGLEPATTERN; 5=REPEATPATTERN (Repeated pattern.); 6=CONTINUOUS (Continuous run (aka Free Run). Count continuously.); 7=ALTPWN (Alternate PWM)
  [5:1] TMRA6CLK — Counter/Timer A6 Clock Select.
    0=TMRPIN (Clock source is TMRPINA.); 1=HFRC_DIV4 (Clock source is the HFRC / 4); 2=HFRC_DIV16 (Clock source is HFRC / 16); 3=HFRC_DIV256 (Clock source is HFRC / 256); 4=HFRC_DIV1024 (Clock source is HFRC / 1024); 5=HFRC_DIV4K (Clock source is HFRC / 4096); 6=XT (Clock source is the XT (uncalibrated).); 7=XT_DIV2 (Clock source is XT / 2); 8=XT_DIV16 (Clock source is XT / 16); 9=XT_DIV128 (Clock source is XT / 128); 10=LFRC_DIV2 (Clock source is LFRC / 2); 11=LFRC_DIV32 (Clock source is LFRC / 32); 12=LFRC_DIV1K (Clock source is LFRC / 1024); 13=LFRC (Clock source is LFRC); 14=RTC_100HZ (Clock source is 100 Hz from the current RTC oscillator.); 15=HCLK_DIV4 (Clock source is HCLK / 4 (note: this clock is only available when MCU is in active mode)); 16=XT_DIV4 (Clock source is XT / 4); 17=XT_DIV8 (Clock source is XT / 8); 18=XT_DIV32 (Clock source is XT / 32); 20=CTMRB6 (Clock source is CTIMERB6 OUT.); 21=CTMRA3 (Clock source is CTIMERA3 OUT.); 22=CTMRB3 (Clock source is CTIMERB3 OUT.); 23=CTMRA7 (Clock source is CTIMERA7 OUT.); 24=CTMRB7 (Clock source is CTIMERB7 OUT.); 25=CTMRB0 (Clock source is CTIMERB0 OUT.); 26=CTMRB1 (Clock source is CTIMERB1 OUT.); 27=CTMRB2 (Clock source is CTIMERB2 OUT.); 28=CTMRB4 (Clock source is CTIMERB4 OUT.); 29=BUCKBLE (Clock source is BLE buck converter TON pulses.); 30=BUCKB (Clock source is Memory buck converter TON pulses.); 31=BUCKA (Clock source is CPU buck converter TON pulses.)
  [0] TMRA6EN — Counter/Timer A6 Enable bit.
    0=DIS (Counter/Timer A6 Disable.); 1=EN (Counter/Timer A6 Enable.)
0xDC AUX6 — Control bit fields for both halves of timer 0.
  [30] TMRB6EN23 — Counter/Timer B6 Upper compare enable.
    values as AUX3.TMRB3EN23
  [29] TMRB6POL23 — Upper output polarity
    values as AUX3.TMRB3POL23
  [28] TMRB6TINV — Counter/Timer B6 Invert on trigger.
    values as AUX3.TMRB3TINV
  [27] TMRB6NOSYNC — Source clock synchronization control.
    values as AUX3.TMRB3NOSYNC
  [26:23] TMRB6TRIG — Counter/Timer B6 Trigger Select.
    0=DIS (Trigger source is disabled.); 1=A6OUT (Trigger source is CTIMERA6 OUT.); 2=B3OUT (Trigger source is CTIMERB3 OUT.); 3=A3OUT (Trigger source is CTIMERA3 OUT.); 4=A4OUT (Trigger source is CTIMERA4 OUT.); 5=B4OUT (Trigger source is CTIMERB4 OUT.); 6=A1OUT (Trigger source is CTIMERA1 OUT.); 7=B1OUT (Trigger source is CTIMERB1 OUT.); 8=B3OUT2 (Trigger source is CTIMERB3 OUT2.); 9=A3OUT2 (Trigger source is CTIMERA3 OUT2.); 10=A2OUT2 (Trigger source is CTIMERA2 OUT2.); 11=B2OUT2 (Trigger source is CTIMERB2 OUT2.); 12=A6OUT2DUAL (Trigger source is CTIMERA6 OUT2, dual edge.); 13=A7OUT2DUAL (Trigger source is CTIMERA7 OUT2, dual edge.); 14=B0OUT2DUAL (Trigger source is CTIMERB0 OUT2, dual edge.); 15=A0OUT2DUAL (Trigger source is CTIMERA0 OUT2, dual edge.)
  [21:16] TMRB6LMT — Counter/Timer B6 Pattern Limit Count.
  [14] TMRA6EN23 — Counter/Timer A6 Upper compare enable.
    values as AUX3.TMRB3EN23
  [13] TMRA6POL23 — Counter/Timer A6 Upper output polarity
    values as AUX3.TMRB3POL23
  [12] TMRA6TINV — Counter/Timer A6 Invert on trigger.
    values as AUX3.TMRB3TINV
  [11] TMRA6NOSYNC — Source clock synchronization control.
    values as AUX3.TMRB3NOSYNC
  [10:7] TMRA6TRIG — Counter/Timer A6 Trigger Select.
    0=DIS (Trigger source is disabled.); 1=B6OUT (Trigger source is CTIMERB6 OUT.); 2=B3OUT (Trigger source is CTIMERB3 OUT.); 3=A3OUT (Trigger source is CTIMERA3 OUT.); 4=A5OUT (Trigger source is CTIMERA5 OUT.); 5=B5OUT (Trigger source is CTIMERB5 OUT.); 6=A1OUT (Trigger source is CTIMERA1 OUT.); 7=B1OUT (Trigger source is CTIMERB1 OUT.); 8=B3OUT2 (Trigger source is CTIMERB3 OUT2.); 9=A3OUT2 (Trigger source is CTIMERA3 OUT2.); 10=A2OUT2 (Trigger source is CTIMERA2 OUT2.); 11=B2OUT2 (Trigger source is CTIMERBb OUT2.); 12=A5OUT2DUAL (Trigger source is CTIMERA5 OUT2, dual edge.); 13=A7OUT2DUAL (Trigger source is CTIMERA7 OUT2, dual edge.); 14=B0OUT2DUAL (Trigger source is CTIMERB0 OUT2, dual edge.); 15=A0OUT2DUAL (Trigger source is CTIMERA0 OUT2, dual edge.)
  [6:0] TMRA6LMT — Counter/Timer A6 Pattern Limit Count.
0xE0 TMR7 — Counter/Timer 7
  [31:16] CTTMRB7 — Counter/Timer B7.
  [15:0] CTTMRA7 — Counter/Timer A7.
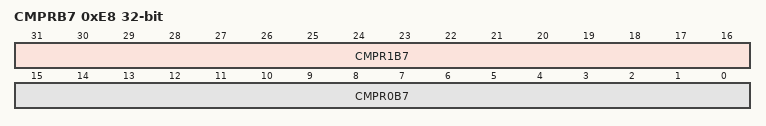
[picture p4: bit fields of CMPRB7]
0xE8 CMPRB7 — This register holds the compare limits for timer half B.
  [31:16] CMPR1B7 — Counter/Timer B3 Compare Register 1.
  [15:0] CMPR0B7 — Counter/Timer B3 Compare Register 0.
